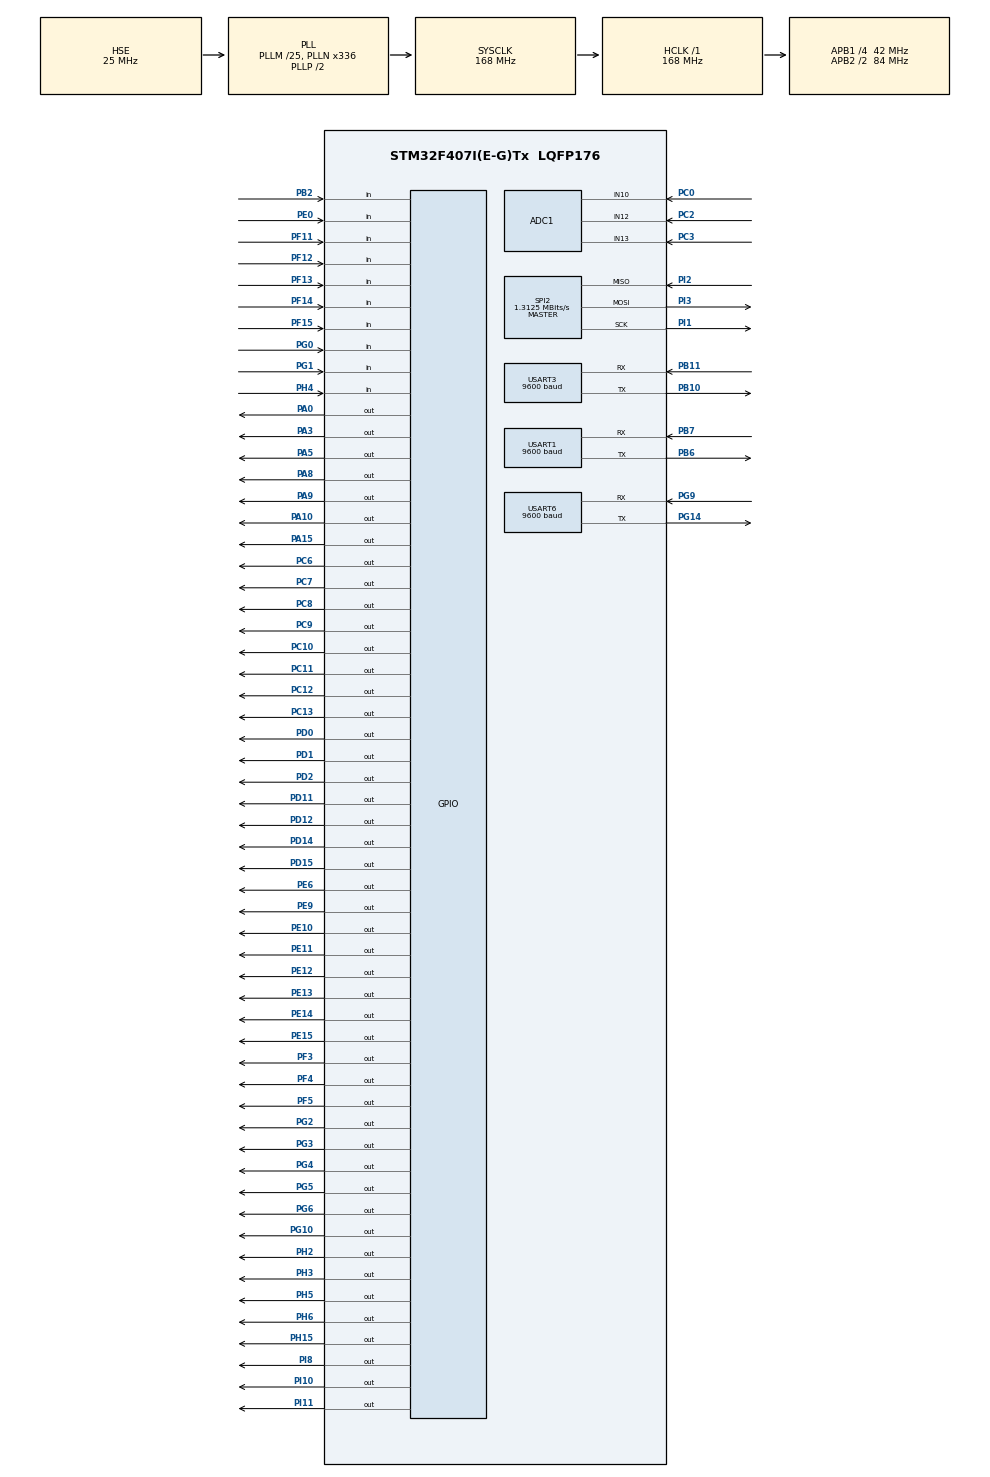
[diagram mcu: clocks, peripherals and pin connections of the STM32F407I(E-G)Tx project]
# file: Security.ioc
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ADC1.Channel-0\#ChannelRegularConversion=ADC_CHANNEL_10
ADC1.Channel-1\#ChannelInjectedConversion=ADC_CHANNEL_10
ADC1.Channel-2\#ChannelInjectedConversion=ADC_CHANNEL_10
ADC1.Channel-3\#ChannelInjectedConversion=ADC_CHANNEL_10
ADC1.InjNumberOfConversion=3
ADC1.InjectedOffset-1\#ChannelInjectedConversion=0
ADC1.InjectedOffset-2\#ChannelInjectedConversion=0
ADC1.InjectedOffset-3\#ChannelInjectedConversion=0
ADC1.InjectedRank-1\#ChannelInjectedConversion=1
ADC1.InjectedRank-2\#ChannelInjectedConversion=2
ADC1.InjectedRank-3\#ChannelInjectedConversion=3
ADC1.NbrOfConversionFlag=1
ADC1.Rank-0\#ChannelRegularConversion=1
ADC1.SamplingTime-0\#ChannelRegularConversion=ADC_SAMPLETIME_3CYCLES
ADC1.SamplingTime-1\#ChannelInjectedConversion=ADC_SAMPLETIME_3CYCLES
ADC1.SamplingTime-2\#ChannelInjectedConversion=ADC_SAMPLETIME_3CYCLES
ADC1.SamplingTime-3\#ChannelInjectedConversion=ADC_SAMPLETIME_3CYCLES
ADC1.ScanConvMode=ENABLE
ADC1.master=1
Dma.Request0=USART3_TX
Dma.Request1=USART3_RX
Dma.Request2=USART6_TX
Dma.Request3=USART6_RX
Dma.USART3_RX.1.Direction=DMA_PERIPH_TO_MEMORY
Dma.USART3_RX.1.FIFOMode=DMA_FIFOMODE_DISABLE
Dma.USART3_RX.1.Instance=DMA1_Stream1
Dma.USART3_RX.1.MemDataAlignment=DMA_MDATAALIGN_BYTE
Dma.USART3_RX.1.MemInc=DMA_MINC_ENABLE
Dma.USART3_RX.1.Mode=DMA_NORMAL
Dma.USART3_RX.1.PeriphDataAlignment=DMA_PDATAALIGN_BYTE
Dma.USART3_RX.1.PeriphInc=DMA_PINC_DISABLE
Dma.USART3_RX.1.Priority=DMA_PRIORITY_LOW
Dma.USART3_TX.0.Direction=DMA_MEMORY_TO_PERIPH
Dma.USART3_TX.0.FIFOMode=DMA_FIFOMODE_DISABLE
Dma.USART3_TX.0.Instance=DMA1_Stream3
Dma.USART3_TX.0.MemDataAlignment=DMA_MDATAALIGN_BYTE
Dma.USART3_TX.0.MemInc=DMA_MINC_ENABLE
Dma.USART3_TX.0.Mode=DMA_NORMAL
Dma.USART3_TX.0.PeriphDataAlignment=DMA_PDATAALIGN_BYTE
Dma.USART3_TX.0.PeriphInc=DMA_PINC_DISABLE
Dma.USART3_TX.0.Priority=DMA_PRIORITY_LOW
Dma.USART6_RX.3.Direction=DMA_PERIPH_TO_MEMORY
Dma.USART6_RX.3.FIFOMode=DMA_FIFOMODE_DISABLE
Dma.USART6_RX.3.Instance=DMA2_Stream1
Dma.USART6_RX.3.MemDataAlignment=DMA_MDATAALIGN_BYTE
Dma.USART6_RX.3.MemInc=DMA_MINC_ENABLE
Dma.USART6_RX.3.Mode=DMA_NORMAL
Dma.USART6_RX.3.PeriphDataAlignment=DMA_PDATAALIGN_BYTE
Dma.USART6_RX.3.PeriphInc=DMA_PINC_DISABLE
Dma.USART6_RX.3.Priority=DMA_PRIORITY_LOW
Dma.USART6_TX.2.Direction=DMA_MEMORY_TO_PERIPH
Dma.USART6_TX.2.FIFOMode=DMA_FIFOMODE_DISABLE
Dma.USART6_TX.2.Instance=DMA2_Stream6
Dma.USART6_TX.2.MemDataAlignment=DMA_MDATAALIGN_BYTE
Dma.USART6_TX.2.MemInc=DMA_MINC_ENABLE
Dma.USART6_TX.2.Mode=DMA_NORMAL
Dma.USART6_TX.2.PeriphDataAlignment=DMA_PDATAALIGN_BYTE
Dma.USART6_TX.2.PeriphInc=DMA_PINC_DISABLE
Dma.USART6_TX.2.Priority=DMA_PRIORITY_LOW
FREERTOS.INCLUDE_vTaskCleanUpResources=1
FREERTOS.INCLUDE_vTaskDelayUntil=1
FREERTOS.INCLUDE_xQueueGetMutexHolder=1
FREERTOS.INCLUDE_xSemaphoreGetMutexHolder=1
FREERTOS.Tasks01=defaultTask,0,128,StartDefaultTask,Default,NULL,Dynamic,NULL,NULL
FREERTOS.configTIMER_TASK_PRIORITY=5
FREERTOS.configTOTAL_HEAP_SIZE=30000
FREERTOS.configUSE_COUNTING_SEMAPHORES=1
FREERTOS.configUSE_NEWLIB_REENTRANT=1
FREERTOS.configUSE_TIMERS=1
IWDG.Prescaler=IWDG_PRESCALER_32
IWDG.Reload=4000
Mcu.Family=STM32F4
Mcu.Name=STM32F407I(E-G)Tx
Mcu.Package=LQFP176
NVIC.DMA1_Stream1_IRQn=true\:5\:0\:false\:false\:true\:true\:false\:true\:true
NVIC.DMA1_Stream3_IRQn=true\:5\:0\:false\:false\:true\:true\:false\:true\:true
NVIC.DMA2_Stream1_IRQn=true\:5\:0\:false\:false\:true\:true\:false\:true\:true
NVIC.DMA2_Stream6_IRQn=true\:5\:0\:false\:false\:true\:true\:false\:true\:true
NVIC.PriorityGroup=NVIC_PRIORITYGROUP_4
NVIC.TIM1_UP_TIM10_IRQn=true\:15\:0\:false\:false\:true\:false\:false\:true\:true
NVIC.TimeBase=TIM1_UP_TIM10_IRQn
NVIC.TimeBaseIP=TIM1
NVIC.USART3_IRQn=true\:5\:0\:false\:false\:true\:true\:true\:true\:true
NVIC.USART6_IRQn=true\:5\:0\:false\:false\:true\:true\:true\:true\:true
PA0-WKUP.PinState=GPIO_PIN_SET
PA0-WKUP.Signal=GPIO_Output
PA10.Signal=GPIO_Output
PA13.Mode=Serial_Wire
PA13.Signal=SYS_JTMS-SWDIO
PA14.Mode=Serial_Wire
PA14.Signal=SYS_JTCK-SWCLK
PA15.PinState=GPIO_PIN_RESET
PA15.Signal=GPIO_Output
PA3.Signal=GPIO_Output
PA5.Signal=GPIO_Output
PA8.Signal=GPIO_Output
PA9.Signal=GPIO_Output
PB10.Mode=Asynchronous
PB10.Signal=USART3_TX
PB11.Mode=Asynchronous
PB11.Signal=USART3_RX
PB2.Signal=GPIO_Input
PB6.Mode=Asynchronous
PB6.Signal=USART1_TX
PB7.Mode=Asynchronous
PB7.Signal=USART1_RX
PC0.Signal=ADCx_IN10
PC10.Signal=GPIO_Output
PC11.Signal=GPIO_Output
PC12.Signal=GPIO_Output
PC13-ANTI_TAMP.Signal=GPIO_Output
PC14-OSC32_IN.Mode=LSE-External-Oscillator
PC14-OSC32_IN.Signal=RCC_OSC32_IN
PC15-OSC32_OUT.Mode=LSE-External-Oscillator
PC15-OSC32_OUT.Signal=RCC_OSC32_OUT
PC2.Signal=ADCx_IN12
PC3.Signal=ADCx_IN13
PC6.PinState=GPIO_PIN_RESET
PC6.Signal=GPIO_Output
PC7.Signal=GPIO_Output
PC8.Signal=GPIO_Output
PC9.Signal=GPIO_Output
PD0.Signal=GPIO_Output
PD1.Signal=GPIO_Output
PD11.GPIO_PuPd=GPIO_PULLDOWN
PD11.Signal=GPIO_Output
PD12.GPIO_PuPd=GPIO_PULLDOWN
PD12.Signal=GPIO_Output
PD14.Signal=GPIO_Output
PD15.Signal=GPIO_Output
PD2.Signal=GPIO_Output
PE0.GPIO_PuPd=GPIO_PULLUP
PE0.Signal=GPIO_Input
PE10.Signal=GPIO_Output
PE11.Signal=GPIO_Output
PE12.Signal=GPIO_Output
PE13.Signal=GPIO_Output
PE14.Signal=GPIO_Output
PE15.Signal=GPIO_Output
PE6.Signal=GPIO_Output
PE9.Signal=GPIO_Output
PF11.Signal=GPIO_Input
PF12.Signal=GPIO_Input
PF13.Signal=GPIO_Input
PF14.Signal=GPIO_Input
PF15.Signal=GPIO_Input
PF3.PinState=GPIO_PIN_SET
PF3.Signal=GPIO_Output
PF4.PinState=GPIO_PIN_SET
PF4.Signal=GPIO_Output
PF5.PinState=GPIO_PIN_SET
PF5.Signal=GPIO_Output
PG0.Signal=GPIO_Input
PG1.Signal=GPIO_Input
PG10.GPIO_PuPd=GPIO_PULLDOWN
PG10.Signal=GPIO_Output
PG14.Mode=Asynchronous
PG14.Signal=USART6_TX
PG2.Signal=GPIO_Output
PG3.Signal=GPIO_Output
PG4.Signal=GPIO_Output
PG5.Signal=GPIO_Output
PG6.Signal=GPIO_Output
PG9.Mode=Asynchronous
PG9.Signal=USART6_RX
PH0-OSC_IN.Mode=HSE-External-Oscillator
PH0-OSC_IN.Signal=RCC_OSC_IN
PH1-OSC_OUT.Mode=HSE-External-Oscillator
PH1-OSC_OUT.Signal=RCC_OSC_OUT
PH15.PinState=GPIO_PIN_SET
PH15.Signal=GPIO_Output
PH2.PinState=GPIO_PIN_SET
PH2.Signal=GPIO_Output
PH3.PinState=GPIO_PIN_SET
PH3.Signal=GPIO_Output
PH4.Signal=GPIO_Input
PH5.Signal=GPIO_Output
PH6.Signal=GPIO_Output
PI1.Mode=Full_Duplex_Master
PI1.Signal=SPI2_SCK
PI10.PinState=GPIO_PIN_SET
PI10.Signal=GPIO_Output
PI11.PinState=GPIO_PIN_SET
PI11.Signal=GPIO_Output
PI2.Mode=Full_Duplex_Master
PI2.Signal=SPI2_MISO
PI3.Mode=Full_Duplex_Master
PI3.Signal=SPI2_MOSI
PI8-\ ANTI\ TAMP2.Signal=GPIO_Output
ProjectManager.HeapSize=0x200
ProjectManager.StackSize=0x400
ProjectManager.TargetToolchain=STM32CubeIDE
RCC.48MHZClocksFreq_Value=84000000
RCC.AHBFreq_Value=168000000
RCC.APB1CLKDivider=RCC_HCLK_DIV4
RCC.APB1Freq_Value=42000000
RCC.APB1TimFreq_Value=84000000
RCC.APB2CLKDivider=RCC_HCLK_DIV2
RCC.APB2Freq_Value=84000000
RCC.APB2TimFreq_Value=168000000
RCC.CortexFreq_Value=168000000
RCC.HCLKFreq_Value=168000000
RCC.HSE_VALUE=25000000
RCC.HSI_VALUE=16000000
RCC.PLLM=25
RCC.PLLN=336
RCC.PLLSourceVirtual=RCC_PLLSOURCE_HSE
RCC.RCC_RTC_Clock_Source=RCC_RTCCLKSOURCE_LSE
RCC.RCC_RTC_Clock_SourceVirtual=RCC_RTCCLKSOURCE_LSE
RCC.SYSCLKFreq_VALUE=168000000
RCC.SYSCLKSource=RCC_SYSCLKSOURCE_PLLCLK
RCC.VCOOutputFreq_Value=336000000
RTC.Date=5
RTC.Hours=17
RTC.Minutes=47
RTC.Month=RTC_MONTH_NOVEMBER
RTC.WeekDay=RTC_WEEKDAY_SATURDAY
RTC.Year=22
SH.ADCx_IN10.0=ADC1_IN10,IN10
SH.ADCx_IN12.0=ADC1_IN12,IN12
SH.ADCx_IN13.0=ADC1_IN13,IN13
SPI2.BaudRatePrescaler=SPI_BAUDRATEPRESCALER_32
SPI2.CalculateBaudRate=1.3125 MBits/s
SPI2.Direction=SPI_DIRECTION_2LINES
SPI2.Mode=SPI_MODE_MASTER
SPI2.VirtualType=VM_MASTER
USART1.BaudRate=9600
USART1.VirtualMode=VM_ASYNC
USART3.BaudRate=9600
USART3.VirtualMode=VM_ASYNC
USART6.BaudRate=9600
USART6.Parity=PARITY_EVEN
USART6.VirtualMode=VM_ASYNC
VP_FREERTOS_VS_CMSIS_V1.Mode=CMSIS_V1
VP_IWDG_VS_IWDG.Mode=IWDG_Activate
VP_RTC_VS_RTC_Activate.Mode=RTC_Enabled
VP_RTC_VS_RTC_Calendar.Mode=RTC_Calendar
VP_SYS_VS_tim1.Mode=TIM1
board=custom

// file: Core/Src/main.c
/* USER CODE BEGIN Header */
/**
  ******************************************************************************
  * @file           : main.c
  * @brief          : Main program body
  ******************************************************************************
  * @attention
  *
  * Copyright (c) 2022 STMicroelectronics.
  * All rights reserved.
  *
  * This software is licensed under terms that can be found in the LICENSE file
  * in the root directory of this software component.
  * If no LICENSE file comes with this software, it is provided AS-IS.
  *
  ******************************************************************************
  */
/* USER CODE END Header */
#include "main.h"
#include "cmsis_os.h"

/* USER CODE BEGIN Includes */

#include "stdio.h"
#include "ibutton.h"
#include "fm25v02.h"
#include "gpio.h"
#include "string.h"
#include "m95.h"
#include "modbus.h"

/* USER CODE END Includes */

 ADC_HandleTypeDef hadc1;

IWDG_HandleTypeDef hiwdg;

RTC_HandleTypeDef hrtc;

SPI_HandleTypeDef hspi2;

UART_HandleTypeDef huart1;
UART_HandleTypeDef huart3;
UART_HandleTypeDef huart6;
DMA_HandleTypeDef hdma_usart3_tx;
DMA_HandleTypeDef hdma_usart3_rx;
DMA_HandleTypeDef hdma_usart6_tx;
DMA_HandleTypeDef hdma_usart6_rx;

osThreadId defaultTaskHandle;
/* USER CODE BEGIN PV */

osMessageQId ModbusQueueHandle;
osMessageQId MeterQueueHandle;
osTimerId AT_TimerHandle;
osTimerId Ring_Center_TimerHandle;
osMutexId UartMutexHandle;
osSemaphoreId TransmissionStateHandle;
osSemaphoreId ReceiveStateHandle;
osSemaphoreId RS485TransmissionStateHandle;

osThreadId IbuttonTaskHandle;
osThreadId SecurityTaskHandle;
osThreadId M95TaskHandle;
osThreadId ModbusTaskHandle;
osThreadId MainTaskHandle;
osThreadId ModbusPacketTaskHandle;
osThreadId CallRingCenterTaskHandle;
osThreadId LedTaskHandle;
osThreadId ArmingTaskHandle;
osThreadId ReadRegistersTaskHandle;
osThreadId EventWriteTaskHandle;
osThreadId GetCurrentTaskHandle;
osThreadId MeterTaskHandle;
osThreadId MeterPacketTaskHandle;

osThreadId CurrentID;
osMutexId Fm25v02MutexHandle;

osSemaphoreId ModbusPacketReceiveHandle;
osSemaphoreId CallRingCenterHandle;

volatile uint8_t security_state = 0x00;
RTC_TimeTypeDef security_time;
RTC_DateTypeDef security_date;

uint8_t flash[20];
uint8_t flash1[20];

uint8_t modem_tx_data[256];
uint8_t modem_rx_data[256];
char modem_rx_buffer[256];
uint8_t modbus_buffer[20][256];
uint8_t modem_rx_number = 0;
uint8_t modbus_buffer_number = 0;

volatile uint8_t read_rx_state;

extern control_register_struct control_registers;

uint8_t meter_data[256];
uint8_t meter_rx_buffer[256];
uint8_t meter_rx_number = 0;

/* USER CODE END PV */

void SystemClock_Config(void);
static void MX_GPIO_Init(void);
static void MX_DMA_Init(void);
static void MX_USART1_UART_Init(void);
static void MX_USART3_UART_Init(void);
static void MX_USART6_UART_Init(void);
static void MX_ADC1_Init(void);
static void MX_IWDG_Init(void);
static void MX_RTC_Init(void);
static void MX_SPI2_Init(void);
void StartDefaultTask(void const * argument);

/* USER CODE BEGIN PFP */

void Callback_AT_Timer(void const * argument);
void Callback_Ring_Center_Timer(void const * argument);

void ThreadIbuttonTask(void const * argument);
void ThreadSecurityTask(void const * argument);
void ThreadM95Task(void const * argument);
void ThreadModbusTask(void const * argument);
void ThreadMainTask(void const * argument);
void ThreadModbusPacketTask(void const * argument);
void ThreadCallRingCenterTask(void const * argument);
void ThreadLedTask(void const * argument);
void ThreadArmingTask(void const * argument);
void ThreadReadRegistersTask(void const * argument);
void ThreadEventWriteTask(void const * argument);
void ThreadGetCurrentTask(void const * argument);
void ThreadMeterTask(void const * argument);
void ThreadMeterPacketTask(void const * argument);

/* USER CODE END PFP */

/* USER CODE BEGIN 0 */

void HAL_UART_TxCpltCallback(UART_HandleTypeDef *huart)
{
	  if (huart->Instance == USART3)
	  {
		  osSemaphoreRelease(TransmissionStateHandle);
	  }

	  if (huart->Instance == USART6)
	  {
		  //LED8_TOGGLE();
		  osSemaphoreRelease(RS485TransmissionStateHandle);
		  HAL_GPIO_WritePin(GPIOG, GPIO_PIN_10, GPIO_PIN_RESET); // устанавливаем микросхему на прием
		  HAL_UART_Receive_DMA(&huart6, &meter_data[0], 1); // включаем прием со счетчика

	  }

}

void HAL_UART_RxCpltCallback(UART_HandleTypeDef *huart)
{

	  if (huart->Instance == USART3)
	  {
		  //LED_VD5_TOGGLE();
		  modem_rx_buffer[modem_rx_number++] = modem_rx_data[0];
		  osMessagePut(ModbusQueueHandle, (uint32_t)modem_rx_data[0], 2000);
		  HAL_UART_Receive_DMA(&huart3, &modem_rx_data[0], 1);
	  }

	  if (huart->Instance == USART6)
	  {
		  //LED7_TOGGLE();
		  meter_data[0] = meter_data[0]&0x7F;
		  meter_rx_buffer[meter_rx_number++] = meter_data[0];
		  HAL_GPIO_WritePin(GPIOG, GPIO_PIN_10, GPIO_PIN_RESET); // устанавливаем микросхему на прием
		  HAL_UART_Receive_DMA(&huart6, &meter_data[0], 1); // включаем прием со счетчика

		  //if(meter_rx_number>10){meter_rx_number=0;}

	  }

}

/* USER CODE END 0 */

int main(void)
{

  /* MCU Configuration--------------------------------------------------------*/

  /* Reset of all peripherals, Initializes the Flash interface and the Systick. */
  HAL_Init();

  /* Configure the system clock */
  SystemClock_Config();

  /* Initialize all configured peripherals */
  MX_GPIO_Init();
  MX_DMA_Init();
  MX_USART1_UART_Init();
  MX_USART3_UART_Init();
  MX_USART6_UART_Init();
  MX_ADC1_Init();
  MX_IWDG_Init();
  MX_RTC_Init();
  MX_SPI2_Init();
  /* USER CODE BEGIN 2 */

  BUZ_ON();
  HAL_Delay(50);
  BUZ_OFF();

  if( ((RCC->BDCR)&0x02) != 0 ) // Проверяем, запустился ли часовой кварц, если запустился включаем светодиод
  {
	  //LED_VD4_ON();
  }
  else
  {
	  //LED_VD4_OFF();
  }

  /* USER CODE END 2 */

  /* USER CODE BEGIN RTOS_MUTEX */
  /* add mutexes, ... */

  osMutexDef(UartMutex);
  UartMutexHandle = osMutexCreate(osMutex(UartMutex));

  osMutexDef(Fm25v02Mutex);
  Fm25v02MutexHandle = osMutexCreate(osMutex(Fm25v02Mutex));

  /* USER CODE END RTOS_MUTEX */

  /* USER CODE BEGIN RTOS_SEMAPHORES */
  /* add semaphores, ... */

  osSemaphoreDef(TransmissionState);
  TransmissionStateHandle = osSemaphoreCreate(osSemaphore(TransmissionState), 1);

  osSemaphoreDef(ReceiveState);
  ReceiveStateHandle = osSemaphoreCreate(osSemaphore(ReceiveState), 1);

  osSemaphoreDef(RS485TransmissionState);
  RS485TransmissionStateHandle = osSemaphoreCreate(osSemaphore(RS485TransmissionState), 1);

  osSemaphoreDef(ModbusPacketReceive);
  ModbusPacketReceiveHandle = osSemaphoreCreate(osSemaphore(ModbusPacketReceive), 1);

  osSemaphoreDef(CallRingCenter);
  CallRingCenterHandle = osSemaphoreCreate(osSemaphore(CallRingCenter), 1);

  /* USER CODE END RTOS_SEMAPHORES */

  /* USER CODE BEGIN RTOS_TIMERS */
  /* start timers, add new ones, ... */

  osTimerDef(AT_Timer, Callback_AT_Timer);
  AT_TimerHandle = osTimerCreate(osTimer(AT_Timer), osTimerOnce, NULL);

  osTimerDef(Ring_Center_Timer, Callback_Ring_Center_Timer);
  Ring_Center_TimerHandle = osTimerCreate(osTimer(Ring_Center_Timer), osTimerOnce, NULL);

  /* USER CODE END RTOS_TIMERS */

  /* USER CODE BEGIN RTOS_QUEUES */
  /* add queues, ... */

  osMessageQDef(ModbusQueue, 256, uint8_t);
  ModbusQueueHandle = osMessageCreate(osMessageQ(ModbusQueue), NULL);

  osMessageQDef(MeterQueue, 256, uint8_t);
  MeterQueueHandle = osMessageCreate(osMessageQ(MeterQueue), NULL);

  /* USER CODE END RTOS_QUEUES */

  /* Create the thread(s) */
  /* definition and creation of defaultTask */
  osThreadDef(defaultTask, StartDefaultTask, osPriorityNormal, 0, 128);
  defaultTaskHandle = osThreadCreate(osThread(defaultTask), NULL);

  /* USER CODE BEGIN RTOS_THREADS */
  /* add threads, ... */

  osThreadDef(IbuttonTask, ThreadIbuttonTask, osPriorityNormal, 0, 128);
  IbuttonTaskHandle = osThreadCreate(osThread(IbuttonTask), NULL);

  osThreadDef(SecurityTask, ThreadSecurityTask, osPriorityNormal, 0, 128);
  SecurityTaskHandle = osThreadCreate(osThread(SecurityTask), NULL);

  osThreadDef(M95Task, ThreadM95Task, osPriorityNormal, 0, 128);
  M95TaskHandle = osThreadCreate(osThread(M95Task), NULL);

  osThreadDef(ModbusTask, ThreadModbusTask, osPriorityNormal, 0, 128);
  ModbusTaskHandle = osThreadCreate(osThread(ModbusTask), NULL);

  osThreadDef(MainTask, ThreadMainTask, osPriorityNormal, 0, 128);
  MainTaskHandle = osThreadCreate(osThread(MainTask), NULL);

  osThreadDef(ModbusPacketTask, ThreadModbusPacketTask, osPriorityNormal, 0, 128);
  ModbusPacketTaskHandle = osThreadCreate(osThread(ModbusPacketTask), NULL);

  osThreadDef(CallRingCenterTask, ThreadCallRingCenterTask, osPriorityNormal, 0, 128);
  CallRingCenterTaskHandle = osThreadCreate(osThread(CallRingCenterTask), NULL);

  osThreadDef(LedTask, ThreadLedTask, osPriorityNormal, 0, 128);
  LedTaskHandle = osThreadCreate(osThread(LedTask), NULL);

  osThreadDef(ArmingTask, ThreadArmingTask, osPriorityNormal, 0, 128);
  ArmingTaskHandle = osThreadCreate(osThread(ArmingTask), NULL);

  osThreadDef(ReadRegistersTask, ThreadReadRegistersTask, osPriorityNormal, 0, 128);
  ReadRegistersTaskHandle = osThreadCreate(osThread(ReadRegistersTask), NULL);

  osThreadDef(EventWriteTask, ThreadEventWriteTask, osPriorityNormal, 0, 128);
  EventWriteTaskHandle = osThreadCreate(osThread(EventWriteTask), NULL);

  osThreadDef(MeterTask, ThreadMeterTask, osPriorityNormal, 0, 128);
  MeterTaskHandle = osThreadCreate(osThread(MeterTask), NULL);

  /* USER CODE END RTOS_THREADS */

  /* Start scheduler */
  osKernelStart();

  /* We should never get here as control is now taken by the scheduler */
  /* Infinite loop */
  while (1)
  {

  }
}

void SystemClock_Config(void)
{
  RCC_OscInitTypeDef RCC_OscInitStruct = {0};
  RCC_ClkInitTypeDef RCC_ClkInitStruct = {0};

  /** Configure the main internal regulator output voltage
  */
  __HAL_RCC_PWR_CLK_ENABLE();
  __HAL_PWR_VOLTAGESCALING_CONFIG(PWR_REGULATOR_VOLTAGE_SCALE1);

  /** Initializes the RCC Oscillators according to the specified parameters
  * in the RCC_OscInitTypeDef structure.
  */
  RCC_OscInitStruct.OscillatorType = RCC_OSCILLATORTYPE_LSI|RCC_OSCILLATORTYPE_HSE
                              |RCC_OSCILLATORTYPE_LSE;
  RCC_OscInitStruct.HSEState = RCC_HSE_ON;
  RCC_OscInitStruct.LSEState = RCC_LSE_ON;
  RCC_OscInitStruct.LSIState = RCC_LSI_ON;
  RCC_OscInitStruct.PLL.PLLState = RCC_PLL_ON;
  RCC_OscInitStruct.PLL.PLLSource = RCC_PLLSOURCE_HSE;
  RCC_OscInitStruct.PLL.PLLM = 25;
  RCC_OscInitStruct.PLL.PLLN = 336;
  RCC_OscInitStruct.PLL.PLLP = RCC_PLLP_DIV2;
  RCC_OscInitStruct.PLL.PLLQ = 4;
  if (HAL_RCC_OscConfig(&RCC_OscInitStruct) != HAL_OK)
  {
    Error_Handler();
  }

  /** Initializes the CPU, AHB and APB buses clocks
  */
  RCC_ClkInitStruct.ClockType = RCC_CLOCKTYPE_HCLK|RCC_CLOCKTYPE_SYSCLK
                              |RCC_CLOCKTYPE_PCLK1|RCC_CLOCKTYPE_PCLK2;
  RCC_ClkInitStruct.SYSCLKSource = RCC_SYSCLKSOURCE_PLLCLK;
  RCC_ClkInitStruct.AHBCLKDivider = RCC_SYSCLK_DIV1;
  RCC_ClkInitStruct.APB1CLKDivider = RCC_HCLK_DIV4;
  RCC_ClkInitStruct.APB2CLKDivider = RCC_HCLK_DIV2;

  if (HAL_RCC_ClockConfig(&RCC_ClkInitStruct, FLASH_LATENCY_5) != HAL_OK)
  {
    Error_Handler();
  }
}

static void MX_ADC1_Init(void)
{

  ADC_ChannelConfTypeDef sConfig = {0};
  ADC_InjectionConfTypeDef sConfigInjected = {0};

  /** Configure the global features of the ADC (Clock, Resolution, Data Alignment and number of conversion)
  */
  hadc1.Instance = ADC1;
  hadc1.Init.ClockPrescaler = ADC_CLOCK_SYNC_PCLK_DIV4;
  hadc1.Init.Resolution = ADC_RESOLUTION_12B;
  hadc1.Init.ScanConvMode = ENABLE;
  hadc1.Init.ContinuousConvMode = DISABLE;
  hadc1.Init.DiscontinuousConvMode = DISABLE;
  hadc1.Init.ExternalTrigConvEdge = ADC_EXTERNALTRIGCONVEDGE_NONE;
  hadc1.Init.ExternalTrigConv = ADC_SOFTWARE_START;
  hadc1.Init.DataAlign = ADC_DATAALIGN_RIGHT;
  hadc1.Init.NbrOfConversion = 1;
  hadc1.Init.DMAContinuousRequests = DISABLE;
  hadc1.Init.EOCSelection = ADC_EOC_SINGLE_CONV;
  if (HAL_ADC_Init(&hadc1) != HAL_OK)
  {
    Error_Handler();
  }

  /** Configure for the selected ADC regular channel its corresponding rank in the sequencer and its sample time.
  */
  sConfig.Channel = ADC_CHANNEL_10;
  sConfig.Rank = 1;
  sConfig.SamplingTime = ADC_SAMPLETIME_3CYCLES;
  if (HAL_ADC_ConfigChannel(&hadc1, &sConfig) != HAL_OK)
  {
    Error_Handler();
  }

  /** Configures for the selected ADC injected channel its corresponding rank in the sequencer and its sample time
  */
  sConfigInjected.InjectedChannel = ADC_CHANNEL_10;
  sConfigInjected.InjectedRank = 1;
  sConfigInjected.InjectedNbrOfConversion = 3;
  sConfigInjected.InjectedSamplingTime = ADC_SAMPLETIME_3CYCLES;
  sConfigInjected.ExternalTrigInjecConvEdge = ADC_EXTERNALTRIGINJECCONVEDGE_NONE;
  sConfigInjected.ExternalTrigInjecConv = ADC_INJECTED_SOFTWARE_START;
  sConfigInjected.AutoInjectedConv = DISABLE;
  sConfigInjected.InjectedDiscontinuousConvMode = DISABLE;
  sConfigInjected.InjectedOffset = 0;
  if (HAL_ADCEx_InjectedConfigChannel(&hadc1, &sConfigInjected) != HAL_OK)
  {
    Error_Handler();
  }

  /** Configures for the selected ADC injected channel its corresponding rank in the sequencer and its sample time
  */
  sConfigInjected.InjectedRank = 2;
  if (HAL_ADCEx_InjectedConfigChannel(&hadc1, &sConfigInjected) != HAL_OK)
  {
    Error_Handler();
  }

  /** Configures for the selected ADC injected channel its corresponding rank in the sequencer and its sample time
  */
  sConfigInjected.InjectedRank = 3;
  if (HAL_ADCEx_InjectedConfigChannel(&hadc1, &sConfigInjected) != HAL_OK)
  {
    Error_Handler();
  }

}

static void MX_IWDG_Init(void)
{

  hiwdg.Instance = IWDG;
  hiwdg.Init.Prescaler = IWDG_PRESCALER_32;
  hiwdg.Init.Reload = 4000;
  if (HAL_IWDG_Init(&hiwdg) != HAL_OK)
  {
    Error_Handler();
  }

}

static void MX_RTC_Init(void)
{

  RTC_TimeTypeDef sTime = {0};
  RTC_DateTypeDef sDate = {0};

  /** Initialize RTC Only
  */
  hrtc.Instance = RTC;
  hrtc.Init.HourFormat = RTC_HOURFORMAT_24;
  hrtc.Init.AsynchPrediv = 127;
  hrtc.Init.SynchPrediv = 255;
  hrtc.Init.OutPut = RTC_OUTPUT_DISABLE;
  hrtc.Init.OutPutPolarity = RTC_OUTPUT_POLARITY_HIGH;
  hrtc.Init.OutPutType = RTC_OUTPUT_TYPE_OPENDRAIN;
  if (HAL_RTC_Init(&hrtc) != HAL_OK)
  {
    Error_Handler();
  }

  /** Initialize RTC and set the Time and Date
  */
  sTime.Hours = 0x17;
  sTime.Minutes = 0x47;
  sTime.Seconds = 0x0;
  sTime.DayLightSaving = RTC_DAYLIGHTSAVING_NONE;
  sTime.StoreOperation = RTC_STOREOPERATION_RESET;
  //if (HAL_RTC_SetTime(&hrtc, &sTime, RTC_FORMAT_BCD) != HAL_OK)
  //{
    //Error_Handler();
  //}
  sDate.WeekDay = RTC_WEEKDAY_SATURDAY;
  sDate.Month = RTC_MONTH_NOVEMBER;
  sDate.Date = 0x5;
  sDate.Year = 0x22;

  //if (HAL_RTC_SetDate(&hrtc, &sDate, RTC_FORMAT_BCD) != HAL_OK)
  //{
    //Error_Handler();
  //}

}

static void MX_SPI2_Init(void)
{

  /* SPI2 parameter configuration*/
  hspi2.Instance = SPI2;
  hspi2.Init.Mode = SPI_MODE_MASTER;
  hspi2.Init.Direction = SPI_DIRECTION_2LINES;
  hspi2.Init.DataSize = SPI_DATASIZE_8BIT;
  hspi2.Init.CLKPolarity = SPI_POLARITY_LOW;
  hspi2.Init.CLKPhase = SPI_PHASE_1EDGE;
  hspi2.Init.NSS = SPI_NSS_SOFT;
  hspi2.Init.BaudRatePrescaler = SPI_BAUDRATEPRESCALER_32;
  hspi2.Init.FirstBit = SPI_FIRSTBIT_MSB;
  hspi2.Init.TIMode = SPI_TIMODE_DISABLE;
  hspi2.Init.CRCCalculation = SPI_CRCCALCULATION_DISABLE;
  hspi2.Init.CRCPolynomial = 10;
  if (HAL_SPI_Init(&hspi2) != HAL_OK)
  {
    Error_Handler();
  }

}

static void MX_USART1_UART_Init(void)
{

  huart1.Instance = USART1;
  huart1.Init.BaudRate = 9600;
  huart1.Init.WordLength = UART_WORDLENGTH_8B;
  huart1.Init.StopBits = UART_STOPBITS_1;
  huart1.Init.Parity = UART_PARITY_NONE;
  huart1.Init.Mode = UART_MODE_TX_RX;
  huart1.Init.HwFlowCtl = UART_HWCONTROL_NONE;
  huart1.Init.OverSampling = UART_OVERSAMPLING_16;
  if (HAL_UART_Init(&huart1) != HAL_OK)
  {
    Error_Handler();
  }

}

static void MX_USART3_UART_Init(void)
{

  huart3.Instance = USART3;
  huart3.Init.BaudRate = 9600;
  huart3.Init.WordLength = UART_WORDLENGTH_8B;
  huart3.Init.StopBits = UART_STOPBITS_1;
  huart3.Init.Parity = UART_PARITY_NONE;
  huart3.Init.Mode = UART_MODE_TX_RX;
  huart3.Init.HwFlowCtl = UART_HWCONTROL_NONE;
  huart3.Init.OverSampling = UART_OVERSAMPLING_16;
  if (HAL_UART_Init(&huart3) != HAL_OK)
  {
    Error_Handler();
  }

}

static void MX_USART6_UART_Init(void)
{

  huart6.Instance = USART6;
  huart6.Init.BaudRate = 9600;
  huart6.Init.WordLength = UART_WORDLENGTH_8B;
  huart6.Init.StopBits = UART_STOPBITS_1;
  huart6.Init.Parity = UART_PARITY_EVEN;
  huart6.Init.Mode = UART_MODE_TX_RX;
  huart6.Init.HwFlowCtl = UART_HWCONTROL_NONE;
  huart6.Init.OverSampling = UART_OVERSAMPLING_16;
  if (HAL_UART_Init(&huart6) != HAL_OK)
  {
    Error_Handler();
  }

}

static void MX_DMA_Init(void)
{

  /* DMA controller clock enable */
  __HAL_RCC_DMA1_CLK_ENABLE();
  __HAL_RCC_DMA2_CLK_ENABLE();

  /* DMA interrupt init */
  /* DMA1_Stream1_IRQn interrupt configuration */
  HAL_NVIC_SetPriority(DMA1_Stream1_IRQn, 5, 0);
  HAL_NVIC_EnableIRQ(DMA1_Stream1_IRQn);
  /* DMA1_Stream3_IRQn interrupt configuration */
  HAL_NVIC_SetPriority(DMA1_Stream3_IRQn, 5, 0);
  HAL_NVIC_EnableIRQ(DMA1_Stream3_IRQn);
  /* DMA2_Stream1_IRQn interrupt configuration */
  HAL_NVIC_SetPriority(DMA2_Stream1_IRQn, 5, 0);
  HAL_NVIC_EnableIRQ(DMA2_Stream1_IRQn);
  /* DMA2_Stream6_IRQn interrupt configuration */
  HAL_NVIC_SetPriority(DMA2_Stream6_IRQn, 5, 0);
  HAL_NVIC_EnableIRQ(DMA2_Stream6_IRQn);

}

static void MX_GPIO_Init(void)
{
  GPIO_InitTypeDef GPIO_InitStruct = {0};

  /* GPIO Ports Clock Enable */
  __HAL_RCC_GPIOE_CLK_ENABLE();
  __HAL_RCC_GPIOI_CLK_ENABLE();
  __HAL_RCC_GPIOC_CLK_ENABLE();
  __HAL_RCC_GPIOF_CLK_ENABLE();
  __HAL_RCC_GPIOH_CLK_ENABLE();
  __HAL_RCC_GPIOA_CLK_ENABLE();
  __HAL_RCC_GPIOB_CLK_ENABLE();
  __HAL_RCC_GPIOG_CLK_ENABLE();
  __HAL_RCC_GPIOD_CLK_ENABLE();

  /*Configure GPIO pin Output Level */
  HAL_GPIO_WritePin(GPIOE, GPIO_PIN_6, GPIO_PIN_RESET);

  /*Configure GPIO pin Output Level */
  HAL_GPIO_WritePin(GPIOI, GPIO_PIN_8, GPIO_PIN_RESET);

  /*Configure GPIO pin Output Level */
  HAL_GPIO_WritePin(GPIOC, GPIO_PIN_13, GPIO_PIN_RESET);

  /*Configure GPIO pin Output Level */
  HAL_GPIO_WritePin(GPIOI, GPIO_PIN_10|GPIO_PIN_11, GPIO_PIN_SET);

  /*Configure GPIO pin Output Level */
  HAL_GPIO_WritePin(GPIOF, GPIO_PIN_3|GPIO_PIN_4|GPIO_PIN_5, GPIO_PIN_SET);

  /*Configure GPIO pin Output Level */
  HAL_GPIO_WritePin(GPIOA, GPIO_PIN_0, GPIO_PIN_SET);

  /*Configure GPIO pin Output Level */
  HAL_GPIO_WritePin(GPIOH, GPIO_PIN_2|GPIO_PIN_3|GPIO_PIN_15, GPIO_PIN_SET);

  /*Configure GPIO pin Output Level */
  HAL_GPIO_WritePin(GPIOH, GPIO_PIN_5|GPIO_PIN_6, GPIO_PIN_RESET);

  /*Configure GPIO pin Output Level */
  HAL_GPIO_WritePin(GPIOA, GPIO_PIN_3|GPIO_PIN_5, GPIO_PIN_RESET);

  /*Configure GPIO pin Output Level */
  HAL_GPIO_WritePin(GPIOD, GPIO_PIN_11|GPIO_PIN_12, GPIO_PIN_RESET);

  /*Configure GPIO pin Output Level */
  HAL_GPIO_WritePin(GPIOG, GPIO_PIN_10, GPIO_PIN_RESET);

  /*Configure GPIO pin : PE6 */
  GPIO_InitStruct.Pin = GPIO_PIN_6;
  GPIO_InitStruct.Mode = GPIO_MODE_OUTPUT_PP;
  GPIO_InitStruct.Pull = GPIO_NOPULL;
  GPIO_InitStruct.Speed = GPIO_SPEED_FREQ_LOW;
  HAL_GPIO_Init(GPIOE, &GPIO_InitStruct);

  /*Configure GPIO pins : PI8 PI10 PI11 */
  GPIO_InitStruct.Pin = GPIO_PIN_8|GPIO_PIN_10|GPIO_PIN_11;
  GPIO_InitStruct.Mode = GPIO_MODE_OUTPUT_PP;
  GPIO_InitStruct.Pull = GPIO_NOPULL;
  GPIO_InitStruct.Speed = GPIO_SPEED_FREQ_LOW;
  HAL_GPIO_Init(GPIOI, &GPIO_InitStruct);

  /*Configure GPIO pin : PC13 */
  GPIO_InitStruct.Pin = GPIO_PIN_13;
  GPIO_InitStruct.Mode = GPIO_MODE_OUTPUT_PP;
  GPIO_InitStruct.Pull = GPIO_NOPULL;
  GPIO_InitStruct.Speed = GPIO_SPEED_FREQ_LOW;
  HAL_GPIO_Init(GPIOC, &GPIO_InitStruct);

  /*Configure GPIO pins : PF3 PF4 PF5 */
  GPIO_InitStruct.Pin = GPIO_PIN_3|GPIO_PIN_4|GPIO_PIN_5;
  GPIO_InitStruct.Mode = GPIO_MODE_OUTPUT_PP;
  GPIO_InitStruct.Pull = GPIO_NOPULL;
  GPIO_InitStruct.Speed = GPIO_SPEED_FREQ_LOW;
  HAL_GPIO_Init(GPIOF, &GPIO_InitStruct);

  /*Configure GPIO pins : PA0 PA3 PA5 */
  GPIO_InitStruct.Pin = GPIO_PIN_0|GPIO_PIN_3|GPIO_PIN_5;
  GPIO_InitStruct.Mode = GPIO_MODE_OUTPUT_PP;
  GPIO_InitStruct.Pull = GPIO_NOPULL;
  GPIO_InitStruct.Speed = GPIO_SPEED_FREQ_LOW;
  HAL_GPIO_Init(GPIOA, &GPIO_InitStruct);

  /*Configure GPIO pins : PH2 PH3 PH5 PH6
                           PH15 */
  GPIO_InitStruct.Pin = GPIO_PIN_2|GPIO_PIN_3|GPIO_PIN_5|GPIO_PIN_6
                          |GPIO_PIN_15;
  GPIO_InitStruct.Mode = GPIO_MODE_OUTPUT_PP;
  GPIO_InitStruct.Pull = GPIO_NOPULL;
  GPIO_InitStruct.Speed = GPIO_SPEED_FREQ_LOW;
  HAL_GPIO_Init(GPIOH, &GPIO_InitStruct);

  /*Configure GPIO pin : PH4 */
  GPIO_InitStruct.Pin = GPIO_PIN_4;
  GPIO_InitStruct.Mode = GPIO_MODE_INPUT;
  GPIO_InitStruct.Pull = GPIO_NOPULL;
  HAL_GPIO_Init(GPIOH, &GPIO_InitStruct);

  /*Configure GPIO pin : PB2 */
  GPIO_InitStruct.Pin = GPIO_PIN_2;
  GPIO_InitStruct.Mode = GPIO_MODE_INPUT;
  GPIO_InitStruct.Pull = GPIO_NOPULL;
  HAL_GPIO_Init(GPIOB, &GPIO_InitStruct);

  /*Configure GPIO pins : PF11 PF12 PF13 PF14
                           PF15 */
  GPIO_InitStruct.Pin = GPIO_PIN_11|GPIO_PIN_12|GPIO_PIN_13|GPIO_PIN_14
                          |GPIO_PIN_15;
  GPIO_InitStruct.Mode = GPIO_MODE_INPUT;
  GPIO_InitStruct.Pull = GPIO_NOPULL;
  HAL_GPIO_Init(GPIOF, &GPIO_InitStruct);

  /*Configure GPIO pins : PG0 PG1 */
  GPIO_InitStruct.Pin = GPIO_PIN_0|GPIO_PIN_1;
  GPIO_InitStruct.Mode = GPIO_MODE_INPUT;
  GPIO_InitStruct.Pull = GPIO_NOPULL;
  HAL_GPIO_Init(GPIOG, &GPIO_InitStruct);

  /*Configure GPIO pins : PD11 PD12 */
  GPIO_InitStruct.Pin = GPIO_PIN_11|GPIO_PIN_12;
  GPIO_InitStruct.Mode = GPIO_MODE_OUTPUT_PP;
  GPIO_InitStruct.Pull = GPIO_PULLDOWN;
  GPIO_InitStruct.Speed = GPIO_SPEED_FREQ_LOW;
  HAL_GPIO_Init(GPIOD, &GPIO_InitStruct);

  /*Configure GPIO pin : PG10 */
  GPIO_InitStruct.Pin = GPIO_PIN_10;
  GPIO_InitStruct.Mode = GPIO_MODE_OUTPUT_PP;
  GPIO_InitStruct.Pull = GPIO_PULLDOWN;
  GPIO_InitStruct.Speed = GPIO_SPEED_FREQ_LOW;
  HAL_GPIO_Init(GPIOG, &GPIO_InitStruct);

  /*Configure GPIO pin : PE0 */
  GPIO_InitStruct.Pin = GPIO_PIN_0;
  GPIO_InitStruct.Mode = GPIO_MODE_INPUT;
  GPIO_InitStruct.Pull = GPIO_PULLUP;
  HAL_GPIO_Init(GPIOE, &GPIO_InitStruct);

}

/* USER CODE BEGIN 4 */

void Callback_AT_Timer(void const * argument)
{

	read_rx_state = NOT_ACTIVE;

}

void Callback_Ring_Center_Timer(void const * argument)
{
	NVIC_SystemReset();
}

/* USER CODE END 4 */

void StartDefaultTask(void const * argument)
{
  /* USER CODE BEGIN 5 */
  /* Infinite loop */
  for(;;)
  {

	HAL_IWDG_Refresh(&hiwdg);
	LED_VD3_TOGGLE();

    osDelay(1000);
  }
  /* USER CODE END 5 */
}

void HAL_TIM_PeriodElapsedCallback(TIM_HandleTypeDef *htim)
{
  if (htim->Instance == TIM1) {
    HAL_IncTick();
  }
}

void Error_Handler(void)
{
  /* USER CODE BEGIN Error_Handler_Debug */

	NVIC_SystemReset();

  /* User can add his own implementation to report the HAL error return state */
  __disable_irq();
  while (1)
  {
  }
  /* USER CODE END Error_Handler_Debug */
}
